AUTOSAR XML (schema 314)
package /ComponentType
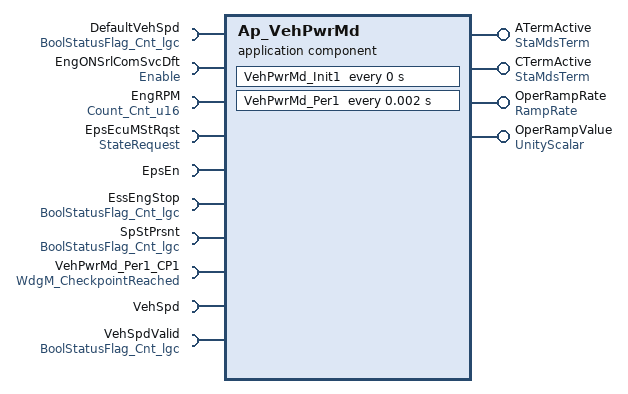
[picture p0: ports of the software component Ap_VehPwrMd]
  application software component type Ap_VehPwrMd
    4 x provide port:
      ATermActive: unqueued-sender-com-spec{data-element=Cnt_lgc, can-invalidate=false, init-value=D_TRUE_CNT_LGC}, provided-interface=StaMdsTerm
      CTermActive: unqueued-sender-com-spec{data-element=Cnt_lgc, can-invalidate=false, init-value=D_FALSE_CNT_LGC}, provided-interface=StaMdsTerm
      OperRampRate: unqueued-sender-com-spec{data-element=XpmS_f32, can-invalidate=false, init-value=D_ZERO_ULS_F32}, provided-interface=RampRate
      OperRampValue: unqueued-sender-com-spec{data-element=Uls_f32, can-invalidate=false, init-value=D_ZERO_ULS_F32}, provided-interface=UnityScalar
    10 x require port:
      DefaultVehSpd: unqueued-receiver-com-spec{data-element=Cnt_lgc, init-value=D_FALSE_CNT_LGC}, required-interface=BoolStatusFlag_Cnt_lgc
      EngONSrlComSvcDft: unqueued-receiver-com-spec{data-element=Cnt_lgc, init-value=D_FALSE_CNT_LGC}, required-interface=Enable
      EngRPM: unqueued-receiver-com-spec{data-element=Cnt_u16, init-value=D_ONE_CNT_U16}, required-interface=Count_Cnt_u16
      EpsEcuMStRqst: required-com-specs=[GetState, ReleasePOSTRUN, ReleaseRUN, RequestPOSTRUN, RequestRUN], required-interface=StateRequest
      EpsEn: client-com-spec=OP_GET, required-interface=EpsEn
      EssEngStop: unqueued-receiver-com-spec{data-element=Cnt_lgc, init-value=D_TRUE_CNT_LGC}, required-interface=BoolStatusFlag_Cnt_lgc
      SpStPrsnt: unqueued-receiver-com-spec{data-element=Cnt_lgc, init-value=D_FALSE_CNT_LGC}, required-interface=BoolStatusFlag_Cnt_lgc
      VehPwrMd_Per1_CP1: client-com-spec=CheckpointReached, required-interface=WdgM_CheckpointReached
      VehSpd: unqueued-receiver-com-spec{data-element=Kph_f32, init-value=D_ZERO_ULS_F32}, required-interface=VehSpd
      VehSpdValid: unqueued-receiver-com-spec{data-element=Cnt_lgc, init-value=D_FALSE_CNT_LGC}, required-interface=BoolStatusFlag_Cnt_lgc
  internal behavior Ap_VehPwrMd_InternalBehavior: component=Ap_VehPwrMd
    timing event VehPwrMd_Init1_InitEvent: start-on-event=VehPwrMd_Init1, period=0
    timing event TMT_VehPwrMd_Per1: start-on-event=VehPwrMd_Per1, period=0.002
    port-api-options:
      enable-take-address=false, indirect-api=false, port=ATermActive
      enable-take-address=false, indirect-api=false, port=CTermActive
      enable-take-address=false, indirect-api=false, port=DefaultVehSpd
      enable-take-address=false, indirect-api=false, port=EngONSrlComSvcDft
      enable-take-address=false, indirect-api=false, port=EngRPM
      enable-take-address=false, indirect-api=false, port=EpsEcuMStRqst
      enable-take-address=false, indirect-api=false, port=EpsEn
      enable-take-address=false, indirect-api=false, port=EssEngStop
      enable-take-address=false, indirect-api=false, port=OperRampRate
      enable-take-address=false, indirect-api=false, port=OperRampValue
      enable-take-address=false, indirect-api=false, port=SpStPrsnt
      enable-take-address=false, indirect-api=false, port=VehPwrMd_Per1_CP1
      enable-take-address=false, indirect-api=false, port=VehSpd
      enable-take-address=false, indirect-api=false, port=VehSpdValid
    runnable VehPwrMd_Init1
      data write access WRITE_OperRampRate_XpmS_f32: data-element=OperRampRate.XpmS_f32
      data write access WRITE_OperRampValue_Uls_f32: data-element=OperRampValue.Uls_f32
    runnable VehPwrMd_Per1
      7 x data read access:
        READ_DefaultVehSpd_Cnt_lgc: data-element=DefaultVehSpd.Cnt_lgc
        READ_EngONSrlComSvcDft_Cnt_lgc: data-element=EngONSrlComSvcDft.Cnt_lgc
        READ_EngRPM_Cnt_u16: data-element=EngRPM.Cnt_u16
        READ_EssEngStop_Cnt_lgc: data-element=EssEngStop.Cnt_lgc
        READ_SpStPrsnt_Cnt_lgc: data-element=SpStPrsnt.Cnt_lgc
        READ_VehSpd_Kph_f32: data-element=VehSpd.Kph_f32
        READ_VehSpdValid_Cnt_lgc: data-element=VehSpdValid.Cnt_lgc
      4 x data write access:
        WRITE_ATermActive_Cnt_lgc: data-element=ATermActive.Cnt_lgc
        WRITE_CTermActive_Cnt_lgc: data-element=CTermActive.Cnt_lgc
        WRITE_OperRampRate_XpmS_f32: data-element=OperRampRate.XpmS_f32
        WRITE_OperRampValue_Uls_f32: data-element=OperRampValue.Uls_f32
      sync call SC_EpsEn_OP_GET: operation=EpsEn.OP_GET, timeout=0
      sync call SC_VehPwrMd_Per1_CP1_CheckpointReached: operation=VehPwrMd_Per1_CP1.CheckpointReached, timeout=0
  swc implementation Ap_VehPwrMd_Implementation: behavior=Ap_VehPwrMd_InternalBehavior
    code-descriptors:
      code Code: type=SRC
